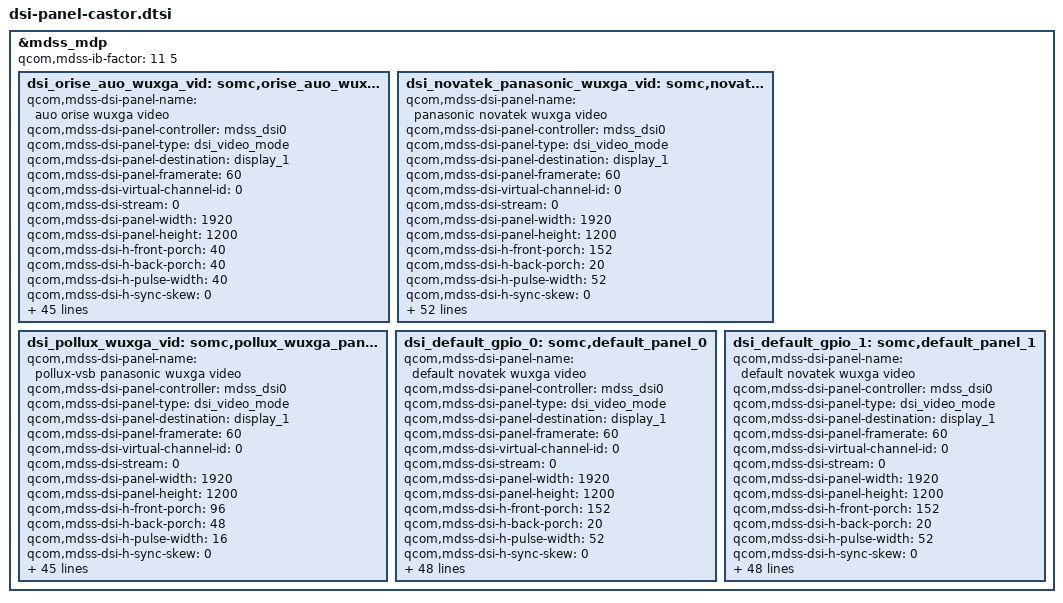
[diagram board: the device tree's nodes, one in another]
/* Copyright (c) 2012, Code Aurora Forum. All rights reserved.
 * Copyright (C) 2012 Sony Mobile Communications Inc.
 *
 * This program is free software; you can redistribute it and/or modify
 * it under the terms of the GNU General Public License version 2 and
 * only version 2 as published by the Free Software Foundation.
 *
 * This program is distributed in the hope that it will be useful,
 * but WITHOUT ANY WARRANTY; without even the implied warranty of
 * MERCHANTABILITY or FITNESS FOR A PARTICULAR PURPOSE.  See the
 * GNU General Public License for more details.
 */

&mdss_mdp {
	qcom,mdss-ib-factor = <11 5>;
	dsi_orise_auo_wuxga_vid: somc,orise_auo_wuxga_panel {
		qcom,mdss-dsi-panel-name = "auo orise wuxga video";
		qcom,mdss-dsi-panel-controller = <&mdss_dsi0>;
		qcom,mdss-dsi-panel-type = "dsi_video_mode";
		qcom,mdss-dsi-panel-destination = "display_1";
		qcom,mdss-dsi-panel-framerate = <60>;
		qcom,mdss-dsi-virtual-channel-id = <0>;
		qcom,mdss-dsi-stream = <0>;
		qcom,mdss-dsi-panel-width = <1920>;
		qcom,mdss-dsi-panel-height = <1200>;
		qcom,mdss-dsi-h-front-porch = <40>;
		qcom,mdss-dsi-h-back-porch = <40>;
		qcom,mdss-dsi-h-pulse-width = <40>;
		qcom,mdss-dsi-h-sync-skew = <0>;
		qcom,mdss-dsi-v-back-porch = <4>;
		qcom,mdss-dsi-v-front-porch = <15>;
		qcom,mdss-dsi-v-pulse-width = <4>;
		qcom,mdss-dsi-h-left-border = <0>;
		qcom,mdss-dsi-h-right-border = <0>;
		qcom,mdss-dsi-v-top-border = <0>;
		qcom,mdss-dsi-v-bottom-border = <0>;
		qcom,mdss-dsi-bpp = <24>;
		qcom,mdss-dsi-underflow-color = <0x0>;
		qcom,mdss-dsi-border-color = <0>;
		qcom,mdss-dsi-h-sync-pulse = <1>;
		qcom,mdss-dsi-traffic-mode = "non_burst_sync_event";
		qcom,mdss-dsi-bllp-eof-power-mode;
		qcom,mdss-dsi-bllp-power-mode;
		qcom,mdss-dsi-lane-0-state;
		qcom,mdss-dsi-lane-1-state;
		qcom,mdss-dsi-lane-2-state;
		qcom,mdss-dsi-lane-3-state;
		qcom,mdss-dsi-panel-timings = [E6 38 26 00 68 6E 2A 3C 2C 03 04 00];
		qcom,mdss-dsi-t-clk-post = <0x02>;
		qcom,mdss-dsi-t-clk-pre = <0x2B>;
		qcom,mdss-dsi-bl-min-level = <1>;
		qcom,mdss-dsi-bl-max-level = <255>;
		qcom,mdss-brightness-max-level = <255>;
		qcom,mdss-dsi-dma-trigger = "trigger_sw";
		qcom,mdss-dsi-mdp-trigger = "none";
		qcom,mdss-dsi-bl-pmic-control-type = "bl_ctrl_wled";
		qcom,mdss-dsi-pan-enable-dynamic-fps;
		qcom,mdss-dsi-pan-fps-update = "dfps_suspend_resume_mode";
		qcom,cont-splash-enabled;

		somc,driver-ic = <3>;
		somc,dric-gpio = <&msmgpio 26 0>;
		somc,mul-channel-scaling = <3>;
		somc,mdss-phy-size-mm = <217 135>;
		somc,mdss-dsi-lane-config = [00 c2 ef 00 00 00 00 01 ff
			00 c2 ef 00 00 00 00 01 ff
			00 c2 ef 00 00 00 00 01 ff
			00 c2 ef 00 00 00 00 01 ff
			00 02 00 00 00 00 00 01 97];
		somc,lcd-id = <1>;
		somc,lcd-id-adc = <0 57000>;
		somc,disp-en-on-post = <200>;
		somc,disp-en-off-pre = <50>;
		somc,pw-down-period = <500>;
	};

	dsi_novatek_panasonic_wuxga_vid: somc,novatek_panasonic_wuxga_panel {
		qcom,mdss-dsi-panel-name = "panasonic novatek wuxga video";
		qcom,mdss-dsi-panel-controller = <&mdss_dsi0>;
		qcom,mdss-dsi-panel-type = "dsi_video_mode";
		qcom,mdss-dsi-panel-destination = "display_1";
		qcom,mdss-dsi-panel-framerate = <60>;
		qcom,mdss-dsi-virtual-channel-id = <0>;
		qcom,mdss-dsi-stream = <0>;
		qcom,mdss-dsi-panel-width = <1920>;
		qcom,mdss-dsi-panel-height = <1200>;
		qcom,mdss-dsi-h-front-porch = <152>;
		qcom,mdss-dsi-h-back-porch = <20>;
		qcom,mdss-dsi-h-pulse-width = <52>;
		qcom,mdss-dsi-h-sync-skew = <0>;
		qcom,mdss-dsi-v-back-porch = <48>;
		qcom,mdss-dsi-v-front-porch = <24>;
		qcom,mdss-dsi-v-pulse-width = <6>;
		qcom,mdss-dsi-h-left-border = <0>;
		qcom,mdss-dsi-h-right-border = <0>;
		qcom,mdss-dsi-v-top-border = <0>;
		qcom,mdss-dsi-v-bottom-border = <0>;
		qcom,mdss-dsi-bpp = <24>;
		qcom,mdss-dsi-underflow-color = <0x0>;
		qcom,mdss-dsi-border-color = <0>;
		qcom,mdss-dsi-on-command = [32 01 00 00 00 00 02 00 00];
		qcom,mdss-dsi-on-command-state = "dsi_lp_mode";
		qcom,mdss-dsi-h-sync-pulse = <1>;
		qcom,mdss-dsi-traffic-mode = "non_burst_sync_event";
		qcom,mdss-dsi-bllp-eof-power-mode;
		qcom,mdss-dsi-bllp-power-mode;
		qcom,mdss-dsi-lane-0-state;
		qcom,mdss-dsi-lane-1-state;
		qcom,mdss-dsi-lane-2-state;
		qcom,mdss-dsi-lane-3-state;
		qcom,mdss-dsi-panel-timings = [FB 3E 2A 00 70 74 2E 42 33 03 04 00];
		qcom,mdss-dsi-t-clk-post = <0x02>;
		qcom,mdss-dsi-t-clk-pre = <0x2E>;
		qcom,mdss-dsi-bl-min-level = <1>;
		qcom,mdss-dsi-bl-max-level = <255>;
		qcom,mdss-brightness-max-level = <255>;
		qcom,mdss-dsi-dma-trigger = "trigger_sw";
		qcom,mdss-dsi-mdp-trigger = "none";
		qcom,mdss-dsi-bl-pmic-control-type = "bl_ctrl_wled";
		qcom,mdss-dsi-pan-enable-dynamic-fps;
		qcom,mdss-dsi-pan-fps-update = "dfps_suspend_resume_mode";
		qcom,cont-splash-enabled;

		somc,driver-ic = <3>;
		somc,dric-gpio = <&msmgpio 26 0>;
		somc,mul-channel-scaling = <3>;
		somc,mdss-phy-size-mm = <217 135>;
		somc,mdss-dsi-lane-config = [00 c2 ef 00 00 00 00 01 ff
			00 c2 ef 00 00 00 00 01 ff
			00 c2 ef 00 00 00 00 01 ff
			00 c2 ef 00 00 00 00 01 ff
			00 02 00 00 00 00 00 01 97];
		somc,lcd-id = <1>;
		somc,lcd-id-adc = <801000 917000>;
		somc,disp-en-on-post = <251>;
		somc,disp-en-off-pre = <86>;
		somc,pw-down-period = <500>;

		somc,mdss-dsi-uv-param-type = <0>;
		somc,mdss-dsi-pcc-table-size = <1>;
		somc,mdss-dsi-pcc-table = <
			0x00 0x01 0x1C 0x1F 0x1C 0x1F 0x8000 0x8000 0x7D80>;
	};

	dsi_pollux_wuxga_vid: somc,pollux_wuxga_panel {
		qcom,mdss-dsi-panel-name = "pollux-vsb panasonic wuxga video";
		qcom,mdss-dsi-panel-controller = <&mdss_dsi0>;
		qcom,mdss-dsi-panel-type = "dsi_video_mode";
		qcom,mdss-dsi-panel-destination = "display_1";
		qcom,mdss-dsi-panel-framerate = <60>;
		qcom,mdss-dsi-virtual-channel-id = <0>;
		qcom,mdss-dsi-stream = <0>;
		qcom,mdss-dsi-panel-width = <1920>;
		qcom,mdss-dsi-panel-height = <1200>;
		qcom,mdss-dsi-h-front-porch = <96>;
		qcom,mdss-dsi-h-back-porch = <48>;
		qcom,mdss-dsi-h-pulse-width = <16>;
		qcom,mdss-dsi-h-sync-skew = <0>;
		qcom,mdss-dsi-v-back-porch = <10>;
		qcom,mdss-dsi-v-front-porch = <23>;
		qcom,mdss-dsi-v-pulse-width = <2>;
		qcom,mdss-dsi-h-left-border = <0>;
		qcom,mdss-dsi-h-right-border = <0>;
		qcom,mdss-dsi-v-top-border = <0>;
		qcom,mdss-dsi-v-bottom-border = <0>;
		qcom,mdss-dsi-bpp = <24>;
		qcom,mdss-dsi-underflow-color = <0x0>;
		qcom,mdss-dsi-border-color = <0>;
		qcom,mdss-dsi-h-sync-pulse = <1>;
		qcom,mdss-dsi-traffic-mode = "non_burst_sync_event";
		qcom,mdss-dsi-bllp-eof-power-mode;
		qcom,mdss-dsi-bllp-power-mode;
		qcom,mdss-dsi-lane-0-state;
		qcom,mdss-dsi-lane-1-state;
		qcom,mdss-dsi-lane-2-state;
		qcom,mdss-dsi-lane-3-state;
		qcom,mdss-dsi-panel-timings = [DE 48 3C 00 64 59 3B 4A 5E 03 04 00];
		qcom,mdss-dsi-t-clk-post = <0x1E>;
		qcom,mdss-dsi-t-clk-pre = <0x38>;
		qcom,mdss-dsi-bl-min-level = <1>;
		qcom,mdss-dsi-bl-max-level = <255>;
		qcom,mdss-brightness-max-level = <255>;
		qcom,mdss-dsi-dma-trigger = "trigger_sw";
		qcom,mdss-dsi-mdp-trigger = "none";
		qcom,mdss-dsi-bl-pmic-control-type = "bl_ctrl_wled";
		qcom,mdss-dsi-pan-enable-dynamic-fps;
		qcom,mdss-dsi-pan-fps-update = "dfps_suspend_resume_mode";
		qcom,cont-splash-enabled;

		somc,driver-ic = <3>;
		somc,dric-gpio = <&msmgpio 26 0>;
		somc,mul-channel-scaling = <3>;
		somc,mdss-phy-size-mm = <217 136>;
		somc,mdss-dsi-lane-config = [00 c2 ef 00 00 00 00 01 75
			00 c2 ef 00 00 00 00 01 75
			00 c2 ef 00 00 00 00 01 75
			00 c2 ef 00 00 00 00 01 75
			00 02 45 00 00 00 00 01 97];
		somc,lcd-id = <1>;
		somc,lcd-id-adc = <1705000 1899000>;
		somc,disp-en-on-post = <251>;
		somc,disp-en-off-pre = <86>;
		somc,pw-down-period = <500>;
	};

	dsi_default_gpio_0: somc,default_panel_0 {
		qcom,mdss-dsi-panel-name = "default novatek wuxga video";
		qcom,mdss-dsi-panel-controller = <&mdss_dsi0>;
		qcom,mdss-dsi-panel-type = "dsi_video_mode";
		qcom,mdss-dsi-panel-destination = "display_1";
		qcom,mdss-dsi-panel-framerate = <60>;
		qcom,mdss-dsi-virtual-channel-id = <0>;
		qcom,mdss-dsi-stream = <0>;
		qcom,mdss-dsi-panel-width = <1920>;
		qcom,mdss-dsi-panel-height = <1200>;
		qcom,mdss-dsi-h-front-porch = <152>;
		qcom,mdss-dsi-h-back-porch = <20>;
		qcom,mdss-dsi-h-pulse-width = <52>;
		qcom,mdss-dsi-h-sync-skew = <0>;
		qcom,mdss-dsi-v-back-porch = <48>;
		qcom,mdss-dsi-v-front-porch = <24>;
		qcom,mdss-dsi-v-pulse-width = <6>;
		qcom,mdss-dsi-h-left-border = <0>;
		qcom,mdss-dsi-h-right-border = <0>;
		qcom,mdss-dsi-v-top-border = <0>;
		qcom,mdss-dsi-v-bottom-border = <0>;
		qcom,mdss-dsi-bpp = <24>;
		qcom,mdss-dsi-underflow-color = <0x0>;
		qcom,mdss-dsi-border-color = <0>;
		qcom,mdss-dsi-on-command = [32 01 00 00 00 00 02 00 00];
		qcom,mdss-dsi-on-command-state = "dsi_lp_mode";
		qcom,mdss-dsi-h-sync-pulse = <1>;
		qcom,mdss-dsi-traffic-mode = "non_burst_sync_event";
		qcom,mdss-dsi-bllp-eof-power-mode;
		qcom,mdss-dsi-bllp-power-mode;
		qcom,mdss-dsi-lane-0-state;
		qcom,mdss-dsi-lane-1-state;
		qcom,mdss-dsi-lane-2-state;
		qcom,mdss-dsi-lane-3-state;
		qcom,mdss-dsi-panel-timings = [FB 3E 2A 00 70 74 2E 42 33 03 04 00];
		qcom,mdss-dsi-t-clk-post = <0x02>;
		qcom,mdss-dsi-t-clk-pre = <0x2E>;
		qcom,mdss-dsi-bl-min-level = <1>;
		qcom,mdss-dsi-bl-max-level = <255>;
		qcom,mdss-brightness-max-level = <255>;
		qcom,mdss-dsi-dma-trigger = "trigger_sw";
		qcom,mdss-dsi-mdp-trigger = "none";
		qcom,mdss-dsi-bl-pmic-control-type = "bl_ctrl_wled";
		qcom,mdss-dsi-pan-enable-dynamic-fps;
		qcom,mdss-dsi-pan-fps-update = "dfps_suspend_resume_mode";
		qcom,cont-splash-enabled;

		somc,driver-ic = <3>;
		somc,dric-gpio = <&msmgpio 26 0>;
		somc,mul-channel-scaling = <3>;
		somc,mdss-phy-size-mm = <217 135>;
		somc,mdss-dsi-lane-config = [00 c2 ef 00 00 00 00 01 75
			00 c2 ef 00 00 00 00 01 75
			00 c2 ef 00 00 00 00 01 75
			00 c2 ef 00 00 00 00 01 75
			00 02 45 00 00 00 00 01 97];
		somc,lcd-id = <0>;
		somc,lcd-id-adc = <0 0x7fffffff>;
		somc,disp-en-on-post = <251>;
		somc,disp-en-off-pre = <86>;
		somc,pw-down-period = <500>;
	};

	dsi_default_gpio_1: somc,default_panel_1 {
		qcom,mdss-dsi-panel-name = "default novatek wuxga video";
		qcom,mdss-dsi-panel-controller = <&mdss_dsi0>;
		qcom,mdss-dsi-panel-type = "dsi_video_mode";
		qcom,mdss-dsi-panel-destination = "display_1";
		qcom,mdss-dsi-panel-framerate = <60>;
		qcom,mdss-dsi-virtual-channel-id = <0>;
		qcom,mdss-dsi-stream = <0>;
		qcom,mdss-dsi-panel-width = <1920>;
		qcom,mdss-dsi-panel-height = <1200>;
		qcom,mdss-dsi-h-front-porch = <152>;
		qcom,mdss-dsi-h-back-porch = <20>;
		qcom,mdss-dsi-h-pulse-width = <52>;
		qcom,mdss-dsi-h-sync-skew = <0>;
		qcom,mdss-dsi-v-back-porch = <48>;
		qcom,mdss-dsi-v-front-porch = <24>;
		qcom,mdss-dsi-v-pulse-width = <6>;
		qcom,mdss-dsi-h-left-border = <0>;
		qcom,mdss-dsi-h-right-border = <0>;
		qcom,mdss-dsi-v-top-border = <0>;
		qcom,mdss-dsi-v-bottom-border = <0>;
		qcom,mdss-dsi-bpp = <24>;
		qcom,mdss-dsi-underflow-color = <0x0>;
		qcom,mdss-dsi-border-color = <0>;
		qcom,mdss-dsi-on-command = [32 01 00 00 00 00 02 00 00];
		qcom,mdss-dsi-on-command-state = "dsi_lp_mode";
		qcom,mdss-dsi-h-sync-pulse = <1>;
		qcom,mdss-dsi-traffic-mode = "non_burst_sync_event";
		qcom,mdss-dsi-bllp-eof-power-mode;
		qcom,mdss-dsi-bllp-power-mode;
		qcom,mdss-dsi-lane-0-state;
		qcom,mdss-dsi-lane-1-state;
		qcom,mdss-dsi-lane-2-state;
		qcom,mdss-dsi-lane-3-state;
		qcom,mdss-dsi-panel-timings = [FB 3E 2A 00 70 74 2E 42 33 03 04 00];
		qcom,mdss-dsi-t-clk-post = <0x02>;
		qcom,mdss-dsi-t-clk-pre = <0x2E>;
		qcom,mdss-dsi-bl-min-level = <1>;
		qcom,mdss-dsi-bl-max-level = <255>;
		qcom,mdss-brightness-max-level = <255>;
		qcom,mdss-dsi-dma-trigger = "trigger_sw";
		qcom,mdss-dsi-mdp-trigger = "none";
		qcom,mdss-dsi-bl-pmic-control-type = "bl_ctrl_wled";
		qcom,mdss-dsi-pan-enable-dynamic-fps;
		qcom,mdss-dsi-pan-fps-update = "dfps_suspend_resume_mode";
		qcom,cont-splash-enabled;

		somc,driver-ic = <3>;
		somc,dric-gpio = <&msmgpio 26 0>;
		somc,mul-channel-scaling = <3>;
		somc,mdss-phy-size-mm = <217 135>;
		somc,mdss-dsi-lane-config = [00 c2 ef 00 00 00 00 01 75
			00 c2 ef 00 00 00 00 01 75
			00 c2 ef 00 00 00 00 01 75
			00 c2 ef 00 00 00 00 01 75
			00 02 45 00 00 00 00 01 97];
		somc,lcd-id = <1>;
		somc,lcd-id-adc = <0 0x7fffffff>;
		somc,disp-en-on-post = <251>;
		somc,disp-en-off-pre = <86>;
		somc,pw-down-period = <500>;
	};
};
